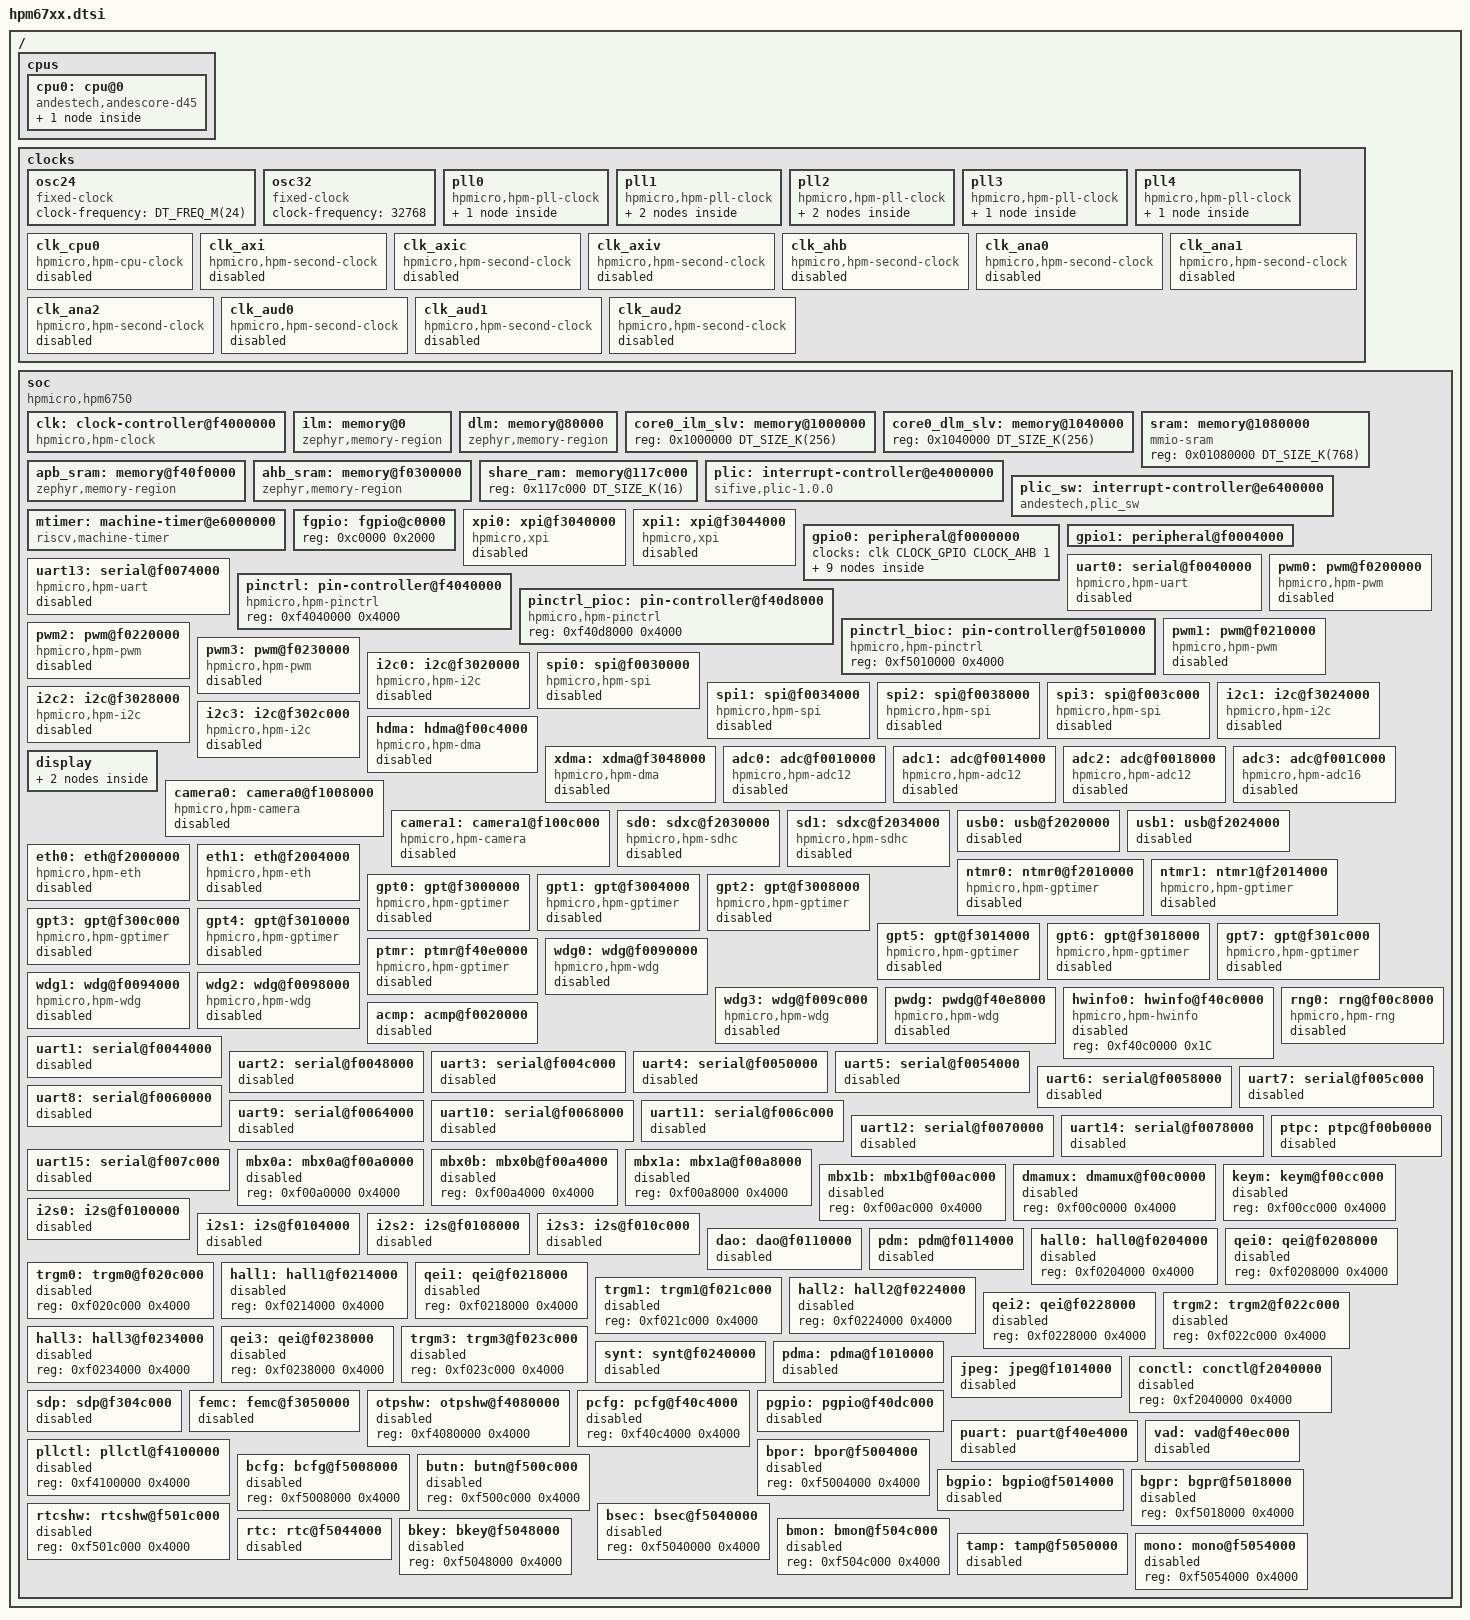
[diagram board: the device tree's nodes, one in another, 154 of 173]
/*
* Copyright 2023-2026 HPMicro
* SPDX-License-Identifier: Apache-2.0
*/

/dts-v1/;
#include <zephyr/dt-bindings/gpio/gpio.h>
#include <zephyr/dt-bindings/i2c/i2c.h>
#include <zephyr/dt-bindings/pwm/pwm.h>
#include <dt-bindings/pwm/hpmicro-pwm-common.h>
#include <mem.h>
#include <freq.h>

/ {
	#address-cells = <1>;
	#size-cells = <1>;
	cpus {
		#address-cells = <1>;
		#size-cells = <0>;
		cpu0: cpu@0 {
			compatible = "andestech,andescore-d45", "riscv";
			reg = <0>;
			status = "okay";
			riscv,isa-base = "rv32i";
			riscv,isa-extensions = "i", "m", "a", "c", "f", "d", "b", "p", "zicsr", "zifencei",
				"xandes";
			i-cache-line-size = <64>;
			d-cache-line-size = <64>;
			cpu0_intc: interrupt-controller {
				compatible = "riscv,cpu-intc";
				#address-cells = <0>;
				#interrupt-cells = <1>;
				interrupt-controller;
			};
		};
	};

	clocks {
		osc24: osc24 {
			#clock-cells = <0>;
			compatible = "fixed-clock";
			clock-frequency = <DT_FREQ_M(24)>;
		};

		osc32: osc32 {
			#clock-cells = <0>;
			compatible = "fixed-clock";
			clock-frequency = <32768>;
		};

		pll0: pll0 {
			#clock-cells = <2>;
			compatible = "hpmicro,hpm-pll-clock";
			pll-frequency = <DT_FREQ_M(648)>;
			pll-index = <0>;
			integer-mode;
			clk0 {
				src-name = <CLK_SRC_PLL0_CLK0>;
				div-i = <0>;
				div-p = <1>;
			};
		};

		pll1: pll1 {
			#clock-cells = <2>;
			compatible = "hpmicro,hpm-pll-clock";
			pll-frequency = <DT_FREQ_M(800)>;
			pll-index = <1>;
			integer-mode;
			clk0 {
				src-name = <CLK_SRC_PLL1_CLK0>;
				div-i = <0>;
				div-p = <3>;
			};

			clk1 {
				src-name = <CLK_SRC_PLL1_CLK1>;
				div-i = <1>;
				div-p = <2>;
			};
		};

		pll2: pll2 {
			#clock-cells = <2>;
			compatible = "hpmicro,hpm-pll-clock";
			pll-frequency = <DT_FREQ_M(1000)>;
			pll-index = <2>;
			integer-mode;
			clk0 {
				src-name = <CLK_SRC_PLL2_CLK0>;
				div-i = <0>;
				div-p = <3>;
			};

			clk1 {
				src-name = <CLK_SRC_PLL2_CLK1>;
				div-i = <1>;
				div-p = <4>;
			};
		};

		pll3: pll3 {
			#clock-cells = <2>;
			compatible = "hpmicro,hpm-pll-clock";
			pll-frequency = <614400001>;
			pll-index = <3>;
			clk0 {
				src-name = <CLK_SRC_PLL3_CLK0>;
				div-i = <0>;
				div-p = <1>;
			};
		};

		pll4: pll4 {
			#clock-cells = <2>;
			compatible = "hpmicro,hpm-pll-clock";
			pll-frequency = <DT_FREQ_M(594)>;
			pll-index = <4>;
			clk0 {
				src-name = <CLK_SRC_PLL4_CLK0>;
				div-i = <0>;
				div-p = <1>;
			};
		};

		clk_cpu0: clk_cpu0 {
			#clock-cells = <0>;
			compatible = "hpmicro,hpm-cpu-clock";
			node-name = <CLOCK_CPU0>;
			clocks = <&pll0 0 2>;
			status = "disabled";
		};

		clk_axi: clk_axi {
			#clock-cells = <0>;
			compatible = "hpmicro,hpm-second-clock";
			node-name = <CLOCK_AXI0>;
			clocks = <&pll1 1 2>;
			status = "disabled";
		};

		clk_axic: clk_axic {
			#clock-cells = <0>;
			compatible = "hpmicro,hpm-second-clock";
			node-name = <CLOCK_AXI1>;
			clocks = <&pll1 1 2>;
			status = "disabled";
		};

		clk_axiv: clk_axiv {
			#clock-cells = <0>;
			compatible = "hpmicro,hpm-second-clock";
			node-name = <CLOCK_AXI2>;
			clocks = <&pll1 1 2>;
			status = "disabled";
		};

		clk_ahb: clk_ahb {
			#clock-cells = <0>;
			compatible = "hpmicro,hpm-second-clock";
			node-name = <CLOCK_AHB>;
			clocks = <&pll1 1 2>;
			status = "disabled";
		};

		clk_ana0: clk_ana0 {
			#clock-cells = <0>;
			compatible = "hpmicro,hpm-second-clock";
			node-name = <CLOCK_ANA0>;
			clocks = <&pll1 1 2>;
			status = "disabled";
		};

		clk_ana1: clk_ana1 {
			#clock-cells = <0>;
			compatible = "hpmicro,hpm-second-clock";
			node-name = <CLOCK_ANA1>;
			clocks = <&pll1 1 2>;
			status = "disabled";
		};

		clk_ana2: clk_ana2 {
			#clock-cells = <0>;
			compatible = "hpmicro,hpm-second-clock";
			node-name = <CLOCK_ANA2>;
			clocks = <&pll1 1 2>;
			status = "disabled";
		};

		clk_aud0: clk_aud0 {
			#clock-cells = <0>;
			compatible = "hpmicro,hpm-second-clock";
			node-name = <CLOCK_AUD0>;
			clocks = <&pll3 0 25>;
			status = "disabled";
		};

		clk_aud1: clk_aud1 {
			#clock-cells = <0>;
			compatible = "hpmicro,hpm-second-clock";
			node-name = <CLOCK_AUD1>;
			clocks = <&pll3 0 25>;
			status = "disabled";
		};

		clk_aud2: clk_aud2 {
			#clock-cells = <0>;
			compatible = "hpmicro,hpm-second-clock";
			node-name = <CLOCK_AUD2>;
			clocks = <&pll3 0 25>;
			status = "disabled";
		};
	};

	soc {
		#address-cells = <1>;
		#size-cells = <1>;
		compatible = "hpmicro,hpm6750";
		ranges;
		clk: clock-controller@f4000000 {
			compatible = "hpmicro,hpm-clock";
			reg = <0xf4000000 DT_SIZE_K(256)
				0xf4100000 DT_SIZE_K(256)>;
			reg-names = "sysctl", "pll";
			status = "okay";
			#clock-cells = <3>;
		};

		ilm: memory@0 {
			compatible = "zephyr,memory-region";
			reg = <0x0 DT_SIZE_K(256)>;
			zephyr,memory-region = "ITCM";
		};

		dlm: memory@80000 {
			compatible = "zephyr,memory-region";
			reg = <0x080000 DT_SIZE_K(256)>;
			zephyr,memory-region = "DTCM";
		};

		core0_ilm_slv: memory@1000000 {
			reg = <0x1000000 DT_SIZE_K(256)>;
		};

		core0_dlm_slv: memory@1040000 {
			reg = <0x1040000 DT_SIZE_K(256)>;
		};

		sram: memory@1080000 {
			compatible = "mmio-sram";
			reg = <0x01080000 DT_SIZE_K(768)>;
		};

		apb_sram: memory@f40f0000 {
			compatible = "zephyr,memory-region";
			reg = <0xf40f0000 DT_SIZE_K(8)>;
			zephyr,memory-region = "APB_SRAM";
		};

		ahb_sram: memory@f0300000 {
			compatible = "zephyr,memory-region";
			reg = <0xf0300000 DT_SIZE_K(32)>;
			zephyr,memory-region = "AHB_SRAM";
		};

		share_ram: memory@117c000 {
			reg = <0x117c000 DT_SIZE_K(16)>;
		};

		plic: interrupt-controller@e4000000 {
			compatible = "sifive,plic-1.0.0";
			#address-cells = <1>;
			#interrupt-cells = <2>;
			interrupt-controller;
			reg = <    0xe4000000 0x00001000
				0xe4002000 0x00000800
				0xe4200000 0x00010000 >;
			reg-names = "prio", "irq_en", "reg";
			riscv,max-priority = <7>;
			riscv,ndev = <128>;
			interrupts-extended = <&cpu0_intc 11>;
		};

		plic_sw: interrupt-controller@e6400000 {
			compatible = "andestech,plic_sw";
			#address-cells = <1>;
			#interrupt-cells = <2>;
			interrupt-controller;
			reg = <0xe6400000 0x00400000>;
			interrupts-extended = <&cpu0_intc 3>;
		};

		mtimer: machine-timer@e6000000 {
			compatible = "riscv,machine-timer";
			clocks = <&clk CLOCK_MCHTMR0 CLK_SRC_OSC24M 24>;
			reg = <0xe6000000 0x8
				0xe6000008 0x8>;
			reg-names = "mtime", "mtimecmp";
			interrupts-extended = <&cpu0_intc 7>;
		};

		fgpio: fgpio@c0000 {
			reg = <0xc0000 0x2000>;
		};

		xpi0: xpi@f3040000 {
			compatible = "hpmicro,xpi";
			reg = <0xf3040000 DT_SIZE_K(16)>;
			clocks = <&clk CLOCK_XPI0 CLK_SRC_PLL1_CLK1 1>;
			#address-cells = <1>;
			#size-cells = <1>;
			status = "disabled";
		};

		xpi1: xpi@f3044000 {
			compatible = "hpmicro,xpi";
			reg = <0xf3044000 DT_SIZE_K(16)>;
			clocks = <&clk CLOCK_XPI1 CLK_SRC_PLL1_CLK1 1>;
			#address-cells = <1>;
			#size-cells = <1>;
			status = "disabled";
		};

		gpio0: peripheral@f0000000 {
			#address-cells = <1>;
			#size-cells = <1>;
			ranges = <0x0 0xf0000000 0x4000>;
			clocks = <&clk CLOCK_GPIO CLOCK_AHB 1>;
		};

		gpio1: peripheral@f0004000 {
			#address-cells = <1>;
			#size-cells = <1>;
			ranges = <0x0 0xf0004000 0x4000>;
		};

		uart0: serial@f0040000 {
			compatible = "hpmicro,hpm-uart";
			reg = <0xf0040000 0x1000>;
			interrupts = <31 1>, <64 1>;
			interrupt-names = "uart", "idletimer";
			clocks = <&clk CLOCK_UART0 CLK_SRC_PLL1_CLK1 5>;
			interrupt-parent = <&plic>;
			status = "disabled";
		};

		uart13: serial@f0074000 {
			compatible = "hpmicro,hpm-uart";
			reg = <0xf0074000 0x1000>;
			interrupts = <44 1>, <65 1>;
			interrupt-names = "uart", "idletimer";
			clocks = <&clk CLOCK_UART13 CLK_SRC_PLL1_CLK1 5>;
			interrupt-parent = <&plic>;
			status = "disabled";
		};

		pinctrl: pin-controller@f4040000 {
			compatible = "hpmicro,hpm-pinctrl";
			reg = <0xf4040000 0x4000>;
			status = "okay";
		};

		pinctrl_pioc: pin-controller@f40d8000 {
			compatible = "hpmicro,hpm-pinctrl";
			reg = <0xf40d8000 0x4000>;
			status = "okay";
		};

		pinctrl_bioc: pin-controller@f5010000 {
			compatible = "hpmicro,hpm-pinctrl";
			reg = <0xf5010000 0x4000>;
			status = "okay";
		};

		pwm0: pwm@f0200000 {
			compatible = "hpmicro,hpm-pwm";
			reg = <0xf0200000 0x10000>;
			clocks = <&clk CLOCK_MOT0 CLOCK_AHB 1>;
			status = "disabled";
			#pwm-cells = <3>;
		};

		pwm1: pwm@f0210000 {
			compatible = "hpmicro,hpm-pwm";
			reg = <0xf0210000 0x10000>;
			clocks = <&clk CLOCK_MOT1 CLOCK_AHB 1>;
			status = "disabled";
			#pwm-cells = <3>;
		};

		pwm2: pwm@f0220000 {
			compatible = "hpmicro,hpm-pwm";
			reg = <0xf0220000 0x10000>;
			clocks = <&clk CLOCK_MOT2 CLOCK_AHB 1>;
			status = "disabled";
			#pwm-cells = <3>;
		};

		pwm3: pwm@f0230000 {
			compatible = "hpmicro,hpm-pwm";
			reg = <0xf0230000 0x10000>;
			clocks = <&clk CLOCK_MOT3 CLOCK_AHB 1>;
			status = "disabled";
			#pwm-cells = <3>;
		};

		i2c0: i2c@f3020000 {
			compatible = "hpmicro,hpm-i2c";
			#address-cells = <1>;
			#size-cells = <0>;
			clocks = <&clk CLOCK_I2C0 CLK_SRC_PLL1_CLK1 5>;
			clock-frequency = <I2C_BITRATE_STANDARD>;
			reg = <0xf3020000 0x4000>;
			interrupts = <68 1>;
			interrupt-parent = <&plic>;
			status = "disabled";
		};

		spi0: spi@f0030000 {
			compatible = "hpmicro,hpm-spi";
			reg = <0xf0030000 0x4000>;
			clocks = <&clk CLOCK_SPI0 CLK_SRC_PLL1_CLK1 5>;
			interrupts = <27 1>;
			interrupt-parent = <&plic>;
			status = "disabled";
			#address-cells = <1>;
			#size-cells = <0>;
			cs-sck-delay = <3>;
			cs-minimum-high-time = <11>;
		};

		spi1: spi@f0034000 {
			compatible = "hpmicro,hpm-spi";
			reg = <0xf0034000 0x4000>;
			clocks = <&clk CLOCK_SPI1 CLK_SRC_PLL1_CLK1 5>;
			interrupts = <28 1>;
			interrupt-parent = <&plic>;
			status = "disabled";
			#address-cells = <1>;
			#size-cells = <0>;
			cs-sck-delay = <3>;
			cs-minimum-high-time = <11>;
		};

		spi2: spi@f0038000 {
			compatible = "hpmicro,hpm-spi";
			reg = <0xf0038000 0x4000>;
			clocks = <&clk CLOCK_SPI2 CLK_SRC_PLL1_CLK1 5>;
			interrupts = <29 1>;
			interrupt-parent = <&plic>;
			status = "disabled";
			#address-cells = <1>;
			#size-cells = <0>;
			cs-sck-delay = <3>;
			cs-minimum-high-time = <11>;
		};

		spi3: spi@f003c000 {
			compatible = "hpmicro,hpm-spi";
			reg = <0xf003c000 0x4000>;
			clocks = <&clk CLOCK_SPI3 CLK_SRC_PLL1_CLK1 5>;
			interrupts = <30 1>;
			interrupt-parent = <&plic>;
			status = "disabled";
			#address-cells = <1>;
			#size-cells = <0>;
			cs-sck-delay = <3>;
			cs-minimum-high-time = <11>;
		};

		i2c1: i2c@f3024000 {
			compatible = "hpmicro,hpm-i2c";
			#address-cells = <1>;
			#size-cells = <0>;
			clocks = <&clk CLOCK_I2C1 CLK_SRC_PLL1_CLK1 5>;
			clock-frequency = <I2C_BITRATE_STANDARD>;
			reg = <0xf3024000 0x4000>;
			interrupts = <69 1>;
			interrupt-parent = <&plic>;
			status = "disabled";
		};

		i2c2: i2c@f3028000 {
			compatible = "hpmicro,hpm-i2c";
			#address-cells = <1>;
			#size-cells = <0>;
			clocks = <&clk CLOCK_I2C2 CLK_SRC_PLL1_CLK1 5>;
			clock-frequency = <I2C_BITRATE_STANDARD>;
			reg = <0xf3028000 0x4000>;
			interrupts = <70 1>;
			interrupt-parent = <&plic>;
			status = "disabled";
		};

		i2c3: i2c@f302c000 {
			compatible = "hpmicro,hpm-i2c";
			#address-cells = <1>;
			#size-cells = <0>;
			clocks = <&clk CLOCK_I2C3 CLK_SRC_PLL1_CLK1 5>;
			clock-frequency = <I2C_BITRATE_STANDARD>;
			reg = <0xf302c000 0x4000>;
			interrupts = <71 1>;
			interrupt-parent = <&plic>;
			status = "disabled";
		};

		hdma: hdma@f00c4000 {
			#dma-cells = <2>;
			compatible = "hpmicro,hpm-dma";
			dma-channels = <8>;
			dma-requests = <116>;
			reg = <0xf00c4000 0x4000>,
				<0xf00c0000 0x4000>; /* DMAMUX base */
				interrupts = <88 1>;
			interrupt-parent = <&plic>;
			clocks = <&clk CLOCK_HDMA CLOCK_AHB 1>;
			status = "disabled";
		};

		xdma: xdma@f3048000 {
			#dma-cells = <2>;
			compatible = "hpmicro,hpm-dma";
			dma-channels = <8>;
			dma-requests = <116>;
			reg = <0xf3048000 0x4000>,
				<0xf00c0000 0x4000>; /* DMAMUX base */
				interrupts = <87 1>;
			interrupt-parent = <&plic>;
			clocks = <&clk CLOCK_XDMA CLOCK_AXI0 1>;
			status = "disabled";
		};

		adc0: adc@f0010000 {
			compatible = "hpmicro,hpm-adc12";
			reg = <0xf0010000 0x4000>;
			interrupts = <19 1>;
			interrupt-parent = <&plic>;
			clocks = <&clk CLOCK_ADC0 CLK_ADC_SRC_AHB0 1>,
				<&clk CLOCK_AHB CLK_SRC_PLL1_CLK1 2>;
			adc-clk-div = <3>;
			sample-time = <20>;
			status = "disabled";
			#io-channel-cells = <1>;
		};

		adc1: adc@f0014000 {
			compatible = "hpmicro,hpm-adc12";
			reg = <0xf0014000 0x4000>;
			interrupts = <20 1>;
			interrupt-parent = <&plic>;
			clocks = <&clk CLOCK_ADC1 CLK_ADC_SRC_AHB0 1>,
				<&clk CLOCK_AHB CLK_SRC_PLL1_CLK1 2>;
			adc-clk-div = <3>;
			sample-time = <20>;
			status = "disabled";
			#io-channel-cells = <1>;
		};

		adc2: adc@f0018000 {
			compatible = "hpmicro,hpm-adc12";
			reg = <0xf0018000 0x4000>;
			interrupts = <21 1>;
			interrupt-parent = <&plic>;
			clocks = <&clk CLOCK_ADC2 CLK_ADC_SRC_AHB0 1>,
				<&clk CLOCK_AHB CLK_SRC_PLL1_CLK1 2>;
			adc-clk-div = <3>;
			sample-time = <20>;
			status = "disabled";
			#io-channel-cells = <1>;
		};

		adc3: adc@f001C000 {
			compatible = "hpmicro,hpm-adc16";
			reg = <0xf001C000 0x4000>;
			interrupts = <22 1>;
			interrupt-parent = <&plic>;
			clocks = <&clk CLOCK_ADC3 CLK_ADC_SRC_AHB0 1>,
				<&clk CLOCK_AHB CLK_SRC_PLL1_CLK1 2>;
			adc-clk-div = <4>;
			sample-time = <20>;
			status = "disabled";
			#io-channel-cells = <1>;
		};

		display {
			#address-cells = <1>;
			#size-cells = <1>;
			lcdc0: lcdc@f1000000 {
				compatible = "hpmicro,hpm-lcdc";
				id = <0>;
				reg = <0xf1000000 DT_SIZE_K(16)>;
				interrupts = <99 1>;
				interrupt-parent = <&plic>;
				clocks = <&clk CLK_PLL4CLK0 CLK_SRC_OSC24M 1>, <&clk CLOCK_DISPLAY CLK_SRC_PLL4_CLK0 8>;
				clock-names = "pll", "lcdc";
				status = "disabled";
			};

			rgb0: rgb {
				compatible = "hpmicro,hpm-rgb";
			};
		};

		camera0: camera0@f1008000 {
			compatible = "hpmicro,hpm-camera";
			clocks = <&clk CLOCK_CAMERA0 CLK_SRC_PLL4_CLK0 10>;
			reg = <0xf1008000 0x4000>;
			interrupts = <97 1>;
			interrupt-parent = <&plic>;
			status = "disabled";
		};

		camera1: camera1@f100c000 {
			compatible = "hpmicro,hpm-camera";
			clocks = <&clk CLOCK_CAMERA1 CLK_SRC_PLL4_CLK0 10>;
			reg = <0xf100c000 0x4000>;
			interrupts = <98 1>;
			interrupt-parent = <&plic>;
			status = "disabled";
		};

		sd0: sdxc@f2030000 {
			compatible = "hpmicro,hpm-sdhc";
			reg = <0xf2030000 0x4000>;
			interrupts = <110 1>;
			interrupt-parent = <&plic>;
			clocks = <&clk CLOCK_SDXC0 CLK_SRC_PLL1_CLK1 2>;
			max-bus-freq = <100000000>;
			min-bus-freq = <400000>;
			status = "disabled";
		};

		sd1: sdxc@f2034000 {
			compatible = "hpmicro,hpm-sdhc";
			reg = <0xf2034000 0x4000>;
			interrupts = <111 1>;
			interrupt-parent = <&plic>;
			clocks = <&clk CLOCK_SDXC1 CLK_SRC_PLL1_CLK1 2>;
			max-bus-freq = <100000000>;
			min-bus-freq = <400000>;
			status = "disabled";
		};

		usb0: usb@f2020000 {
			clk-name = <CLOCK_USB0>;
			reg = <0xf2020000 0x4000>;
			interrupts = <106 1>;
			interrupt-parent = <&plic>;
			clocks = <&clk CLOCK_USB0 CLOCK_AXI1 1>;
			num-bidir-endpoints = <8>;
			status = "disabled";
		};

		usb1: usb@f2024000 {
			clk-name = <CLOCK_USB1>;
			reg = <0xf2024000 0x4000>;
			interrupts = <107 1>;
			interrupt-parent = <&plic>;
			clocks = <&clk CLOCK_USB1 CLOCK_AXI1 1>;
			num-bidir-endpoints = <8>;
			status = "disabled";
		};

		eth0: eth@f2000000 {
			compatible = "hpmicro,hpm-eth";
			clocks = <&clk CLOCK_ETH0 CLK_SRC_PLL2_CLK1 2>;
			reg = <0xf2000000 0x4000>;
			interrupts = <108 1>;
			interrupt-parent = <&plic>;
			status = "disabled";
		};

		eth1: eth@f2004000 {
			compatible = "hpmicro,hpm-eth";
			clocks = <&clk CLOCK_ETH1 CLK_SRC_PLL2_CLK1 2>;
			reg = <0xf2004000 0x4000>;
			interrupts = <109 1>;
			interrupt-parent = <&plic>;
			status = "disabled";
		};

		ntmr0: ntmr0@f2010000 {
			compatible = "hpmicro,hpm-gptimer";
			reg = <0xf2010000 0x4000>;
			interrupts = <104 1>;
			interrupt-parent = <&plic>;
			clocks = <&clk CLOCK_NTMR0 CLK_SRC_PLL1_CLK1 4>;
			status = "disabled";
		};

		ntmr1: ntmr1@f2014000 {
			compatible = "hpmicro,hpm-gptimer";
			reg = <0xf2014000 0x4000>;
			interrupts = <105 1>;
			interrupt-parent = <&plic>;
			clocks = <&clk CLOCK_NTMR1 CLK_SRC_PLL1_CLK1 4>;
			status = "disabled";
		};

		gpt0: gpt@f3000000 {
			compatible = "hpmicro,hpm-gptimer";
			reg = <0xf3000000 0x4000>;
			interrupts = <60 1>;
			interrupt-parent = <&plic>;
			gptfreq = <100000000>;
			clocks = <&clk CLOCK_GPTMR0 CLK_SRC_PLL1_CLK1 4>;
			status = "disabled";
		};

		gpt1: gpt@f3004000 {
			compatible = "hpmicro,hpm-gptimer";
			reg = <0xf3004000 0x4000>;
			interrupts = <61 1>;
			interrupt-parent = <&plic>;
			gptfreq = <100000000>;
			clocks = <&clk CLOCK_GPTMR1 CLK_SRC_PLL1_CLK1 4>;
			status = "disabled";
		};

		gpt2: gpt@f3008000 {
			compatible = "hpmicro,hpm-gptimer";
			reg = <0xf3008000 0x4000>;
			interrupts = <62 1>;
			interrupt-parent = <&plic>;
			gptfreq = <100000000>;
			clocks = <&clk CLOCK_GPTMR2 CLK_SRC_PLL1_CLK1 4>;
			status = "disabled";
		};

		gpt3: gpt@f300c000 {
			compatible = "hpmicro,hpm-gptimer";
			reg = <0xf300c000 0x4000>;
			interrupts = <63 1>;
			interrupt-parent = <&plic>;
			gptfreq = <100000000>;
			clocks = <&clk CLOCK_GPTMR3 CLK_SRC_PLL1_CLK1 4>;
			status = "disabled";
		};

		gpt4: gpt@f3010000 {
			compatible = "hpmicro,hpm-gptimer";
			reg = <0xf3010000 0x4000>;
			interrupts = <64 1>;
			interrupt-parent = <&plic>;
			gptfreq = <100000000>;
			clocks = <&clk CLOCK_GPTMR4 CLK_SRC_PLL1_CLK1 4>;
			status = "disabled";
		};

		gpt5: gpt@f3014000 {
			compatible = "hpmicro,hpm-gptimer";
			reg = <0xf3014000 0x4000>;
			interrupts = <65 1>;
			interrupt-parent = <&plic>;
			gptfreq = <100000000>;
			clocks = <&clk CLOCK_GPTMR5 CLK_SRC_PLL1_CLK1 4>;
			status = "disabled";
		};

		gpt6: gpt@f3018000 {
			compatible = "hpmicro,hpm-gptimer";
			reg = <0xf3018000 0x4000>;
			interrupts = <66 1>;
			interrupt-parent = <&plic>;
			gptfreq = <100000000>;
			clocks = <&clk CLOCK_GPTMR6 CLK_SRC_PLL1_CLK1 4>;
			status = "disabled";
		};

		gpt7: gpt@f301c000 {
			compatible = "hpmicro,hpm-gptimer";
			reg = <0xf301c000 0x4000>;
			interrupts = <67 1>;
			interrupt-parent = <&plic>;
			gptfreq = <100000000>;
			clocks = <&clk CLOCK_GPTMR7 CLK_SRC_PLL1_CLK1 4>;
			status = "disabled";
		};

		ptmr: ptmr@f40e0000 {
			compatible = "hpmicro,hpm-gptimer";
			reg = <0xf40e0000 0x4000>;
			interrupts = <115 1>;
			interrupt-parent = <&plic>;
			clocks = <&clk CLOCK_PTMR CLK_SRC_OSC24M 1>;
			status = "disabled";
		};

		wdg0: wdg@f0090000 {
			compatible = "hpmicro,hpm-wdg";
			reg = <0xf0090000 0x4000>;
			interrupts = <52 1>;
			interrupt-parent = <&plic>;
			clocks = <&clk CLOCK_WATCHDOG0 CLK_WDG_SRC_OSC32K 1>;
			status = "disabled";
		};

		wdg1: wdg@f0094000 {
			compatible = "hpmicro,hpm-wdg";
			reg = <0xf0094000 0x4000>;
			interrupts = <53 1>;
			interrupt-parent = <&plic>;
			clocks = <&clk CLOCK_WATCHDOG1 CLK_WDG_SRC_OSC32K 1>;
			status = "disabled";
		};

		wdg2: wdg@f0098000 {
			compatible = "hpmicro,hpm-wdg";
			reg = <0xf0098000 0x4000>;
			interrupts = <54 1>;
			interrupt-parent = <&plic>;
			clocks = <&clk CLOCK_WATCHDOG2 CLK_WDG_SRC_OSC32K 1>;
			status = "disabled";
		};

		wdg3: wdg@f009c000 {
			compatible = "hpmicro,hpm-wdg";
			reg = <0xf009c000 0x4000>;
			interrupts = <55 1>;
			interrupt-parent = <&plic>;
			clocks = <&clk CLOCK_WATCHDOG3 CLK_WDG_SRC_OSC32K 1>;
			status = "disabled";
		};

		pwdg: pwdg@f40e8000 {
			compatible = "hpmicro,hpm-wdg";
			reg = <0xf40e8000 0x4000>;
			interrupts = <114 1>;
			interrupt-parent = <&plic>;
			clocks = <&clk CLOCK_PWDG CLK_PWDG_SRC_OSC32K 1>;
			status = "disabled";
		};

		hwinfo0: hwinfo@f40c0000 {
			compatible = "hpmicro,hpm-hwinfo";
			reg = <0xf40c0000 0x1C>;
			status = "disabled";
		};

		rng0: rng@f00c8000 {
			compatible = "hpmicro,hpm-rng";
			clk-name = <CLOCK_RNG>;
			clk-source = <0>;
			clk-divider = <0>;
			reg = <0xf00c8000 0x4000>;
			interrupts = <90 1>;
			interrupt-parent = <&plic>;
			clocks = <&clk CLOCK_RNG CLOCK_AHB 1>;
			status = "disabled";
		};

		acmp: acmp@f0020000 {
			reg = <0xf0020000 0x4000>;
			clocks = <&clk CLOCK_ACMP0 CLOCK_AHB 1>;
			status = "disabled";
		};

		uart1: serial@f0044000 {
			reg = <0xf0044000 0x4000>;
			clocks = <&clk CLOCK_UART1 CLK_SRC_PLL1_CLK1 5>;
			status = "disabled";
		};

		uart2: serial@f0048000 {
			reg = <0xf0048000 0x4000>;
			clocks = <&clk CLOCK_UART2 CLK_SRC_PLL1_CLK1 5>;
			status = "disabled";
		};

		uart3: serial@f004c000 {
			reg = <0xf004c000 0x4000>;
			clocks = <&clk CLOCK_UART3 CLK_SRC_PLL1_CLK1 5>;
			status = "disabled";
		};

		uart4: serial@f0050000 {
			reg = <0xf0050000 0x4000>;
			clocks = <&clk CLOCK_UART4 CLK_SRC_PLL1_CLK1 5>;
			status = "disabled";
		};

		uart5: serial@f0054000 {
			reg = <0xf0054000 0x4000>;
			clocks = <&clk CLOCK_UART5 CLK_SRC_PLL1_CLK1 5>;
			status = "disabled";
		};

		uart6: serial@f0058000 {
			reg = <0xf0058000 0x4000>;
			clocks = <&clk CLOCK_UART6 CLK_SRC_PLL1_CLK1 5>;
			status = "disabled";
		};

		uart7: serial@f005c000 {
			reg = <0xf005c000 0x4000>;
			clocks = <&clk CLOCK_UART7 CLK_SRC_PLL1_CLK1 5>;
			status = "disabled";
		};

		uart8: serial@f0060000 {
			reg = <0xf0060000 0x4000>;
			clocks = <&clk CLOCK_UART8 CLK_SRC_PLL1_CLK1 5>;
			status = "disabled";
		};

		uart9: serial@f0064000 {
			reg = <0xf0064000 0x4000>;
			clocks = <&clk CLOCK_UART9 CLK_SRC_PLL1_CLK1 5>;
			status = "disabled";
		};

		uart10: serial@f0068000 {
			reg = <0xf0068000 0x4000>;
			clocks = <&clk CLOCK_UART10 CLK_SRC_PLL1_CLK1 5>;
			status = "disabled";
		};

		uart11: serial@f006c000 {
			reg = <0xf006c000 0x4000>;
			clocks = <&clk CLOCK_UART11 CLK_SRC_PLL1_CLK1 5>;
			status = "disabled";
		};

		uart12: serial@f0070000 {
			reg = <0xf0070000 0x4000>;
			clocks = <&clk CLOCK_UART12 CLK_SRC_PLL1_CLK1 5>;
			status = "disabled";
		};

		uart14: serial@f0078000 {
			reg = <0xf0078000 0x4000>;
			clocks = <&clk CLOCK_UART14 CLK_SRC_PLL1_CLK1 5>;
			status = "disabled";
		};

		uart15: serial@f007c000 {
			reg = <0xf007c000 0x4000>;
			clocks = <&clk CLOCK_UART15 CLK_SRC_PLL1_CLK1 5>;
			status = "disabled";
		};

		mbx0a: mbx0a@f00a0000 {
			reg = <0xf00a0000 0x4000>;
			status = "disabled";
		};

		mbx0b: mbx0b@f00a4000 {
			reg = <0xf00a4000 0x4000>;
			status = "disabled";
		};

		mbx1a: mbx1a@f00a8000 {
			reg = <0xf00a8000 0x4000>;
			status = "disabled";
		};

		mbx1b: mbx1b@f00ac000 {
			reg = <0xf00ac000 0x4000>;
			status = "disabled";
		};

		ptpc: ptpc@f00b0000 {
			reg = <0xf00b0000 0x4000>;
			clocks = <&clk CLOCK_PTPC CLK_SRC_PLL1_CLK1 4>;
			status = "disabled";
		};

		dmamux: dmamux@f00c0000 {
			reg = <0xf00c0000 0x4000>;
			status = "disabled";
		};

		keym: keym@f00cc000 {
			reg = <0xf00cc000 0x4000>;
			status = "disabled";
		};

		i2s0: i2s@f0100000 {
			reg = <0xf0100000 0x4000>;
			clocks = <&clk CLOCK_I2S0 CLK_I2S_SRC_AUD0 1>,
				<&clk CLOCK_AUD0 CLK_SRC_PLL3_CLK0 25>;
			status = "disabled";
		};

		i2s1: i2s@f0104000 {
			reg = <0xf0104000 0x4000>;
			clocks = <&clk CLOCK_I2S1 CLK_I2S_SRC_AUD0 1>,
				<&clk CLOCK_AUD0 CLK_SRC_PLL3_CLK0 25>;
			status = "disabled";
		};

		i2s2: i2s@f0108000 {
			reg = <0xf0108000 0x4000>;
			clocks = <&clk CLOCK_I2S2 CLK_I2S_SRC_AUD0 1>,
				<&clk CLOCK_AUD0 CLK_SRC_PLL3_CLK0 25>;
			status = "disabled";
		};

		i2s3: i2s@f010c000 {
			reg = <0xf010c000 0x4000>;
			clocks = <&clk CLOCK_I2S3 CLK_I2S_SRC_AUD0 1>,
				<&clk CLOCK_AUD0 CLK_SRC_PLL3_CLK0 25>;
			status = "disabled";
		};

		dao: dao@f0110000 {
			reg = <0xf0110000 0x4000>;
			clocks = <&clk CLOCK_DAO CLK_I2S_SRC_AHB0 1>,
				<&clk CLOCK_AHB CLK_SRC_PLL1_CLK1 2>;
			status = "disabled";
		};

		pdm: pdm@f0114000 {
			reg = <0xf0114000 0x4000>;
			clocks = <&clk CLOCK_PDM CLK_I2S_SRC_AHB0 1>,
				<&clk CLOCK_AHB CLK_SRC_PLL1_CLK1 2>;
			status = "disabled";
		};

		hall0: hall0@f0204000 {
			reg = <0xf0204000 0x4000>;
			status = "disabled";
		};

		qei0: qei@f0208000 {
			reg = <0xf0208000 0x4000>;
			status = "disabled";
		};

		trgm0: trgm0@f020c000 {
			reg = <0xf020c000 0x4000>;
			status = "disabled";
		};

		hall1: hall1@f0214000 {
			reg = <0xf0214000 0x4000>;
			status = "disabled";
		};

		qei1: qei@f0218000 {
			reg = <0xf0218000 0x4000>;
			status = "disabled";
		};

		trgm1: trgm1@f021c000 {
			reg = <0xf021c000 0x4000>;
			status = "disabled";
		};

		hall2: hall2@f0224000 {
			reg = <0xf0224000 0x4000>;
			status = "disabled";
		};

		qei2: qei@f0228000 {
			reg = <0xf0228000 0x4000>;
			status = "disabled";
		};

		trgm2: trgm2@f022c000 {
			reg = <0xf022c000 0x4000>;
			status = "disabled";
		};

		hall3: hall3@f0234000 {
			reg = <0xf0234000 0x4000>;
			status = "disabled";
		};

		qei3: qei@f0238000 {
			reg = <0xf0238000 0x4000>;
			status = "disabled";
		};

		trgm3: trgm3@f023c000 {
			reg = <0xf023c000 0x4000>;
			status = "disabled";
		};

		synt: synt@f0240000 {
			reg = <0xf0240000 0x4000>;
			clocks = <&clk CLOCK_SYNT CLOCK_AHB 1>;
			status = "disabled";
		};

		pdma: pdma@f1010000 {
			reg = <0xf1010000 0x4000>;
			clocks = <&clk CLOCK_PDMA CLOCK_AXI2 1>;
			status = "disabled";
		};

		jpeg: jpeg@f1014000 {
			reg = <0xf1014000 0x4000>;
			clocks = <&clk CLOCK_JPEG CLOCK_AXI2 1>;
			status = "disabled";
		};

		conctl: conctl@f2040000 {
			reg = <0xf2040000 0x4000>;
			status = "disabled";
		};

		sdp: sdp@f304c000 {
			reg = <0xf304c000 0x4000>;
			clocks = <&clk CLOCK_SDP CLOCK_AXI0 1>;
			status = "disabled";
		};

		femc: femc@f3050000 {
			reg = <0xf3050000 0x4000>;
			clocks = <&clk CLOCK_FEMC CLK_SRC_PLL2_CLK0 2>;
			status = "disabled";
		};

		otpshw: otpshw@f4080000 {
			reg = <0xf4080000 0x4000>;
			status = "disabled";
		};

		pcfg: pcfg@f40c4000 {
			reg = <0xf40c4000 0x4000>;
			status = "disabled";
		};

		pgpio: pgpio@f40dc000 {
			reg = <0xf40dc000 0x4000>;
			clocks = <&osc24>;
			status = "disabled";
		};

		puart: puart@f40e4000 {
			reg = <0xf40e4000 0x4000>;
			clocks = <&clk CLOCK_PUART CLK_SRC_OSC24M 1>;
			status = "disabled";
		};

		vad: vad@f40ec000 {
			reg = <0xf40ec000 0x4000>;
			clocks = <&osc24>;
			status = "disabled";
		};

		pllctl: pllctl@f4100000 {
			reg = <0xf4100000 0x4000>;
			status = "disabled";
		};

		bpor: bpor@f5004000 {
			reg = <0xf5004000 0x4000>;
			status = "disabled";
		};

		bcfg: bcfg@f5008000 {
			reg = <0xf5008000 0x4000>;
			status = "disabled";
		};

		butn: butn@f500c000 {
			reg = <0xf500c000 0x4000>;
			status = "disabled";
		};

		bgpio: bgpio@f5014000 {
			reg = <0xf5014000 0x4000>;
			clocks = <&osc32>;
			status = "disabled";
		};

		bgpr: bgpr@f5018000 {
			reg = <0xf5018000 0x4000>;
			status = "disabled";
		};

		rtcshw: rtcshw@f501c000 {
			reg = <0xf501c000 0x4000>;
			status = "disabled";
		};

		bsec: bsec@f5040000 {
			reg = <0xf5040000 0x4000>;
			status = "disabled";
		};

		rtc: rtc@f5044000 {
			reg = <0xf5044000 0x4000>;
			clocks = <&osc32>;
			status = "disabled";
		};

		bkey: bkey@f5048000 {
			reg = <0xf5048000 0x4000>;
			status = "disabled";
		};

		bmon: bmon@f504c000 {
			reg = <0xf504c000 0x4000>;
			status = "disabled";
		};

		tamp: tamp@f5050000 {
			reg = <0xf5050000 0x4000>;
			clocks = <&osc32>;
			status = "disabled";
		};

		mono: mono@f5054000 {
			reg = <0xf5054000 0x4000>;
			status = "disabled";
		};
	};
};

&gpio0 {
	gpioa: gpio@0 {
		compatible = "hpmicro,hpm-gpio";
		reg = <0x0 0x4000>;
		gpio-controller;
		#gpio-cells = <2>;
		hpmicro-gpio-port = <0>;
		interrupts = <1 1>;
		interrupt-parent = <&plic>;
	};

	gpiob: gpio@1 {
		compatible = "hpmicro,hpm-gpio";
		reg = <0x0 0x4000>;
		gpio-controller;
		#gpio-cells = <2>;
		hpmicro-gpio-port = <1>;
		interrupts = <2 1>;
		interrupt-parent = <&plic>;
	};

	gpioc: gpio@2 {
		compatible = "hpmicro,hpm-gpio";
		reg = <0x0 0x4000>;
		gpio-controller;
		#gpio-cells = <2>;
		hpmicro-gpio-port = <2>;
		interrupts = <3 1>;
		interrupt-parent = <&plic>;
	};

	gpiod: gpio@3 {
		compatible = "hpmicro,hpm-gpio";
		reg = <0x0 0x4000>;
		gpio-controller;
		#gpio-cells = <2>;
		hpmicro-gpio-port = <3>;
		interrupts = <4 1>;
		interrupt-parent = <&plic>;
	};

	gpioe: gpio@4 {
		compatible = "hpmicro,hpm-gpio";
		reg = <0x0 0x4000>;
		gpio-controller;
		#gpio-cells = <2>;
		hpmicro-gpio-port = <4>;
		interrupts = <5 1>;
		interrupt-parent = <&plic>;
	};

	gpiof: gpio@5 {
		compatible = "hpmicro,hpm-gpio";
		reg = <0x0 0x4000>;
		gpio-controller;
		#gpio-cells = <2>;
		hpmicro-gpio-port = <5>;
		interrupts = <6 1>;
		interrupt-parent = <&plic>;
	};

	gpiox: gpio@7 {
		compatible = "hpmicro,hpm-gpio";
		reg = <0x0 0x4000>;
		gpio-controller;
		#gpio-cells = <2>;
		hpmicro-gpio-port = <13>;
		interrupt-parent = <&plic>;
		interrupts = <7 1>;
		status = "disabled";
	};

	gpioy: gpio@8 {
		compatible = "hpmicro,hpm-gpio";
		reg = <0x0 0x4000>;
		gpio-controller;
		#gpio-cells = <2>;
		hpmicro-gpio-port = <14>;
		interrupts = <8 1>;
		interrupt-parent = <&plic>;
		status = "disabled";
	};

	gpioz: gpio@9 {
		compatible = "hpmicro,hpm-gpio";
		reg = <0x0 0x4000>;
		gpio-controller;
		#gpio-cells = <2>;
		hpmicro-gpio-port = <15>;
		interrupts = <9 1>;
		interrupt-parent = <&plic>;
		status = "disabled";
	};
};
